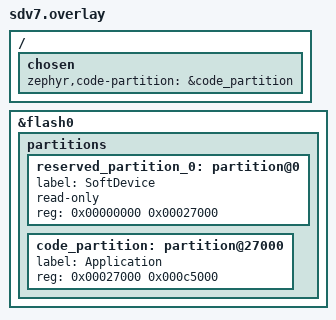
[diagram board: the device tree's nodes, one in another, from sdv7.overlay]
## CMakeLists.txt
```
# SPDX-License-Identifier: Apache-2.0
#
# TouchBridge Digitizer: nRF52840 USB multitouch bridge (CDC ACM in, HID touch screen out)

cmake_minimum_required(VERSION 3.20.0)

find_package(Zephyr REQUIRED HINTS $ENV{ZEPHYR_BASE})
project(touchbridge_digitizer)

target_sources(app PRIVATE src/main.c src/tb_proto.c src/tb_report.c)
```

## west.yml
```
# west manifest for the TouchBridge Digitizer firmware.
# Pins Zephyr (same version as the Auracaster dongle) and fetches only what an
# nRF52840 USB device needs.
manifest:
  self:
    path: nrf-digitizer
  remotes:
    - name: zephyrproject-rtos
      url-base: https://github.com/zephyrproject-rtos
  projects:
    - name: zephyr
      remote: zephyrproject-rtos
      revision: v4.4.2
      import:
        name-allowlist:
          - cmsis_6
          - hal_nordic
```

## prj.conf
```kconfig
# TouchBridge Digitizer - USB composite device (CDC ACM + HID touch screen)

# --- System -------------------------------------------------------------------
CONFIG_GPIO=y
CONFIG_HWINFO=y
CONFIG_RING_BUFFER=y
CONFIG_MAIN_STACK_SIZE=2048
CONFIG_SYSTEM_WORKQUEUE_STACK_SIZE=1024
# no console / logging: the CDC ACM port carries the TouchBridge protocol
CONFIG_CONSOLE=n
CONFIG_STDOUT_CONSOLE=n
CONFIG_UART_CONSOLE=n
CONFIG_LOG=n
CONFIG_SERIAL=y
CONFIG_UART_INTERRUPT_DRIVEN=y
# DTR (host opened the port) and baud rate (1200 baud touch -> UF2 bootloader)
CONFIG_UART_LINE_CTRL=y

# --- USB device stack (device_next) ------------------------------------------
# The board's own CDC ACM boot initialisation is replaced by src/main.c, which
# registers CDC ACM and HID in one configuration (VID/PID 2fe3:0010).
CONFIG_USB_DEVICE_STACK_NEXT=y
CONFIG_CDC_ACM_SERIAL_INITIALIZE_AT_BOOT=n
CONFIG_USBD_CDC_ACM_CLASS=y
CONFIG_USBD_HID_SUPPORT=y
# 1 report in flight + 1 spare
CONFIG_USBD_HID_IN_BUF_COUNT=2
```

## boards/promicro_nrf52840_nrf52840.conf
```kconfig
# "nosd" variant: board promicro_nrf52840/nrf52840 (without /uf2).
# Linked at 0x1000 right behind the Nordic MBR, for clones whose UF2
# bootloader reports "SoftDevice: not found" in INFO_UF2.TXT.
CONFIG_BUILD_OUTPUT_UF2=y
```

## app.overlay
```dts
/*
 * HID touch screen interface of the TouchBridge Digitizer. The CDC ACM
 * interface is the board's board_cdc_acm_uart node (boards/common/usb/cdc_acm_serial.dtsi).
 *
 * SPDX-License-Identifier: Apache-2.0
 */

/ {
	touch_hid: touch_hid {
		compatible = "zephyr,hid-device";
		label = "TouchBridge Digitizer";
		protocol-code = "none";
		/* 1 ms interrupt IN endpoint, 64-byte report 1 (incl. report ID) */
		in-polling-period-us = <1000>;
		in-report-size = <64>;
	};
};
```

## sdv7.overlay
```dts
/*
 * Optional layout for UF2 bootloaders shipped with SoftDevice S140 v7.x
 * (INFO_UF2.TXT: "SoftDevice: S140 version 7.x.x"): application at 0x27000.
 * Applied on top of promicro_nrf52840/nrf52840/uf2 (default: S140 v6, 0x26000).
 *
 * SPDX-License-Identifier: Apache-2.0
 */

/delete-node/ &reserved_partition_0;
/delete-node/ &code_partition;

/ {
	chosen {
		zephyr,code-partition = &code_partition;
	};
};

&flash0 {
	partitions {
		reserved_partition_0: partition@0 {
			label = "SoftDevice";
			read-only;
			reg = <0x00000000 0x00027000>;
		};

		code_partition: partition@27000 {
			label = "Application";
			reg = <0x00027000 0x000c5000>;
		};
	};
};
```

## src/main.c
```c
/*
 * TouchBridge Digitizer - nRF52840 USB multitouch bridge (Pro Micro nRF52840 / nice!nano v2).
 *
 * USB composite device 2fe3:0010 "TouchBridge Digitizer" (Zephyr device_next stack):
 *   - CDC ACM: TouchBridge on the Mac sends contact frames (PROTOCOL.md)
 *   - HID touch screen (Digitizer 0x0D / Touch Screen 0x04, 10 contacts):
 *     every frame is re-emitted as HID input report 1, so macOS sees a real
 *     USB digitizer instead of synthetic events.
 *
 * Safety: all contacts are lifted when no frame arrives for 200 ms while a
 * finger is down, when the host closes the port (DTR 0) and on TB_MSG_RELEASE_ALL.
 * "1200 baud touch" or TB_MSG_BOOTLOADER reboots into the UF2 bootloader.
 *
 * SPDX-License-Identifier: Apache-2.0
 */

#include <string.h>

#include <zephyr/kernel.h>
#include <zephyr/device.h>
#include <zephyr/drivers/gpio.h>
#include <zephyr/drivers/uart.h>
#include <zephyr/linker/linker-defs.h>
#include <zephyr/sys/ring_buffer.h>
#include <zephyr/sys/atomic.h>
#include <zephyr/usb/usbd.h>
#include <zephyr/usb/class/usbd_hid.h>

#include <soc.h>
#include <app_version.h>

#include "tb_proto.h"
#include "tb_report.h"

#define TB_VID 0x2FE3
#define TB_PID 0x0010

#define RELEASE_TIMEOUT_MS 200
#define TOUCH_BAUD         1200U
#define UF2_RESET_MAGIC    0x57 /* DFU_MAGIC_UF2_RESET (Adafruit nRF52 bootloader) */

/* hello reply flags */
#define HELLO_FLAG_BOOTLOADER_CMD BIT(0)
#define HELLO_FLAG_TOUCH_1200     BIT(1)

static const uint8_t hid_report_desc[] = {
#include "hid_report_desc.inc"
};

static const struct device *const cdc_dev = DEVICE_DT_GET(DT_NODELABEL(board_cdc_acm_uart));
static const struct device *const hid_dev = DEVICE_DT_GET(DT_NODELABEL(touch_hid));

/* ------------------------------------------------------------------ USB device */

USBD_DEVICE_DEFINE(tb_usbd, DEVICE_DT_GET(DT_NODELABEL(zephyr_udc0)), TB_VID, TB_PID);
USBD_DESC_LANG_DEFINE(tb_lang);
USBD_DESC_MANUFACTURER_DEFINE(tb_mfr, "TouchBridge");
USBD_DESC_PRODUCT_DEFINE(tb_product, "TouchBridge Digitizer");
USBD_DESC_SERIAL_NUMBER_DEFINE(tb_sn);
USBD_DESC_CONFIG_DEFINE(tb_fs_cfg_desc, "FS Configuration");
/* bus powered, 100 mA */
USBD_CONFIGURATION_DEFINE(tb_fs_config, 0, 50, &tb_fs_cfg_desc);

static int usb_setup(void)
{
	int err;

	err = usbd_add_descriptor(&tb_usbd, &tb_lang);
	err = err ? err : usbd_add_descriptor(&tb_usbd, &tb_mfr);
	err = err ? err : usbd_add_descriptor(&tb_usbd, &tb_product);
	err = err ? err : usbd_add_descriptor(&tb_usbd, &tb_sn);
	err = err ? err : usbd_add_configuration(&tb_usbd, USBD_SPEED_FS, &tb_fs_config);
	err = err ? err : usbd_register_all_classes(&tb_usbd, USBD_SPEED_FS, 1, NULL);
	if (err) {
		return err;
	}
	/* CDC ACM has an Interface Association Descriptor */
	usbd_device_set_code_triple(&tb_usbd, USBD_SPEED_FS, USB_BCC_MISCELLANEOUS, 0x02, 0x01);
	usbd_self_powered(&tb_usbd, false);
	err = usbd_init(&tb_usbd);
	return err ? err : usbd_enable(&tb_usbd);
}

/* ------------------------------------------------------------------ status LED */

enum led_mode { LED_NO_USB, LED_WAITING, LED_CONNECTED, LED_TOUCHING };
static atomic_t led_mode = ATOMIC_INIT(LED_NO_USB);

#if DT_NODE_EXISTS(DT_ALIAS(led0))
static const struct gpio_dt_spec led = GPIO_DT_SPEC_GET(DT_ALIAS(led0), gpios);

/*   no USB host      : short blip every 2 s
 *   USB, port closed : slow blink (1 Hz)
 *   TouchBridge open : steady on
 *   finger(s) down   : fast blink (5 Hz)
 */
static void led_thread(void *a, void *b, void *c)
{
	ARG_UNUSED(a); ARG_UNUSED(b); ARG_UNUSED(c);
	uint32_t tick = 0;

	if (!gpio_is_ready_dt(&led) || gpio_pin_configure_dt(&led, GPIO_OUTPUT_INACTIVE)) {
		return;
	}
	while (true) {
		bool on;

		switch (atomic_get(&led_mode)) {
		case LED_TOUCHING:  on = (tick & 1U) == 0U; break;
		case LED_CONNECTED: on = true; break;
		case LED_WAITING:   on = (tick % 10U) < 5U; break;
		default:            on = (tick % 20U) == 0U; break;
		}
		gpio_pin_set_dt(&led, on);
		tick++;
		k_msleep(100);
	}
}
K_THREAD_DEFINE(led_tid, 512, led_thread, NULL, NULL, NULL, K_LOWEST_APPLICATION_THREAD_PRIO, 0, 0);
#endif

/* ------------------------------------------------------------------ CDC ACM */

RING_BUF_DECLARE(rx_ring, 1024);
RING_BUF_DECLARE(tx_ring, 256);
static K_SEM_DEFINE(wake_sem, 0, 1);

static void cdc_irq(const struct device *dev, void *user_data)
{
	ARG_UNUSED(user_data);

	while (uart_irq_update(dev) && uart_irq_is_pending(dev)) {
		if (uart_irq_rx_ready(dev)) {
			uint8_t buf[64];
			int n = uart_fifo_read(dev, buf, sizeof(buf));

			if (n > 0) {
				(void)ring_buf_put(&rx_ring, buf, n); /* overflow: bytes dropped, CRC catches it */
				k_sem_give(&wake_sem);
			}
		}
		if (uart_irq_tx_ready(dev)) {
			uint8_t buf[64];
			uint32_t n = ring_buf_peek(&tx_ring, buf, sizeof(buf));

			if (n == 0) {
				uart_irq_tx_disable(dev);
			} else {
				int sent = uart_fifo_fill(dev, buf, n);

				if (sent > 0) {
					ring_buf_get(&tx_ring, NULL, sent);
				}
			}
		}
	}
}

static void send_msg(const uint8_t *payload, uint8_t len)
{
	uint8_t frame[TB_MAX_PAYLOAD + 3];
	size_t n = tb_encode_frame(payload, len, frame, sizeof(frame));

	if (n == 0) {
		return;
	}
	unsigned int key = irq_lock();

	if (ring_buf_space_get(&tx_ring) >= n) {
		ring_buf_put(&tx_ring, frame, n);
	}
	irq_unlock(key);
	uart_irq_tx_enable(cdc_dev);
}

/* ------------------------------------------------------------------ firmware identity */

static uint8_t fw_variant(void)
{
	switch ((uint32_t)(uintptr_t)_vector_start) {
	case 0x26000: return 1; /* s140v6 */
	case 0x27000: return 2; /* s140v7 */
	case 0x1000:  return 3; /* nosd   */
	default:      return 0;
	}
}

static void send_hello_reply(void)
{
	uint32_t load = (uint32_t)(uintptr_t)_vector_start;
	uint8_t p[] = {
		TB_MSG_HELLO_REPLY, TB_PROTO_VERSION,
		APP_VERSION_MAJOR, APP_VERSION_MINOR, APP_PATCHLEVEL,
		TB_MAX_CONTACTS, fw_variant(), HELLO_FLAG_BOOTLOADER_CMD | HELLO_FLAG_TOUCH_1200,
		(uint8_t)load, (uint8_t)(load >> 8), (uint8_t)(load >> 16), (uint8_t)(load >> 24),
		'T', 'B', 'D', 'G',
	};

	send_msg(p, sizeof(p));
}

static void send_error(uint8_t code)
{
	uint8_t p[] = { TB_MSG_ERROR, code };

	send_msg(p, sizeof(p));
}

static FUNC_NORETURN void enter_uf2_bootloader(void)
{
	(void)irq_lock();
	/* read and cleared by the Adafruit nRF52 bootloader after reset */
	NRF_POWER->GPREGRET = UF2_RESET_MAGIC;
	NVIC_SystemReset();
	CODE_UNREACHABLE;
}

/* ------------------------------------------------------------------ HID */

static atomic_t hid_ready;
static atomic_t hid_busy;
static struct tb_report_state rstate;
/* latest report waiting for the IN endpoint (coalesced while one is in flight) */
static uint8_t pending_report[TB_REPORT_SIZE];
static bool have_pending;
UDC_STATIC_BUF_DEFINE(tx_report, TB_REPORT_SIZE);

static void hid_iface_ready(const struct device *dev, const bool ready)
{
	ARG_UNUSED(dev);
	atomic_set(&hid_ready, ready);
	if (!ready) {
		atomic_set(&hid_busy, 0);
	}
	k_sem_give(&wake_sem);
}

static int hid_get_report(const struct device *dev, const uint8_t type, const uint8_t id,
			  const uint16_t len, uint8_t *const buf)
{
	ARG_UNUSED(dev);
	if (type == HID_REPORT_TYPE_FEATURE && id == TB_REPORT_ID_MAX_COUNT && len >= 2) {
		buf[0] = TB_REPORT_ID_MAX_COUNT;
		buf[1] = TB_MAX_CONTACTS;
		return 2;
	}
	if (type == HID_REPORT_TYPE_INPUT && id == TB_REPORT_ID_INPUT && len >= TB_REPORT_SIZE) {
		/* current state: nothing down after a GET_REPORT is acceptable */
		memset(buf, 0, TB_REPORT_SIZE);
		buf[0] = TB_REPORT_ID_INPUT;
		return TB_REPORT_SIZE;
	}
	return -ENOTSUP;
}

static int hid_set_report(const struct device *dev, const uint8_t type, const uint8_t id,
			  const uint16_t len, const uint8_t *const buf)
{
	ARG_UNUSED(dev); ARG_UNUSED(type); ARG_UNUSED(id); ARG_UNUSED(len); ARG_UNUSED(buf);
	return 0; /* nothing configurable; accept so hosts do not stall */
}

static void hid_report_done(const struct device *dev, const uint8_t *const report)
{
	ARG_UNUSED(dev); ARG_UNUSED(report);
	atomic_set(&hid_busy, 0);
	k_sem_give(&wake_sem);
}

static const struct hid_device_ops hid_ops = {
	.iface_ready = hid_iface_ready,
	.get_report = hid_get_report,
	.set_report = hid_set_report,
	.input_report_done = hid_report_done,
};

static void hid_flush(void)
{
	if (!have_pending || !atomic_get(&hid_ready) || atomic_get(&hid_busy)) {
		return;
	}
	memcpy(tx_report, pending_report, TB_REPORT_SIZE);
	atomic_set(&hid_busy, 1);
	if (hid_device_submit_report(hid_dev, TB_REPORT_SIZE, tx_report) != 0) {
		atomic_set(&hid_busy, 0);
		return; /* keep it pending, retried on the next wake-up */
	}
	have_pending = false;
}

static uint16_t scan_time(void)
{
	/* 100 us units, wraps at 65535 */
	return (uint16_t)(k_ticks_to_us_floor64(k_uptime_ticks()) / 100U);
}

static void queue_frame(const struct tb_touch_frame *f)
{
	uint8_t old[TB_REPORT_SIZE];
	bool had_pending = have_pending;

	if (had_pending) {
		memcpy(old, pending_report, sizeof(old));
	}
	tb_report_build(&rstate, f, scan_time(), pending_report);
	if (had_pending) {
		/* the unsent report is replaced: keep its lifts (tip = 0 entries),
		 * otherwise the OS would never see those contacts go up */
		tb_report_merge_lifts(pending_report, old);
	}
	have_pending = true;
	hid_flush();
}

static void release_all(void)
{
	if (!tb_report_any_down(&rstate)) {
		return;
	}
	struct tb_touch_frame none = { .count = 0 };

	queue_frame(&none);
}

/* ------------------------------------------------------------------ main loop */

static void handle_payload(const uint8_t *p, int len, int64_t *last_frame)
{
	switch (p[0]) {
	case TB_MSG_TOUCH: {
		struct tb_touch_frame f;
		int err = tb_decode_touch(p, (size_t)len, &f);

		if (err) {
			send_error((uint8_t)err);
			return;
		}
		*last_frame = k_uptime_get();
		queue_frame(&f);
		break;
	}
	case TB_MSG_HELLO:
		send_hello_reply();
		break;
	case TB_MSG_RELEASE_ALL:
		release_all();
		break;
	case TB_MSG_BOOTLOADER:
		k_msleep(50);
		enter_uf2_bootloader();
	default:
		send_error(TB_ERR_TYPE);
		break;
	}
}

int main(void)
{
	static struct tb_parser parser;
	int64_t last_frame = 0;
	uint32_t last_dtr = 0;

	tb_parser_init(&parser);
	tb_report_init(&rstate);

	if (!device_is_ready(cdc_dev) || !device_is_ready(hid_dev)) {
		return 0;
	}
	if (hid_device_register(hid_dev, hid_report_desc, sizeof(hid_report_desc), &hid_ops)) {
		return 0;
	}
	if (usb_setup()) {
		return 0;
	}
	uart_irq_callback_set(cdc_dev, cdc_irq);
	uart_irq_rx_enable(cdc_dev);

	while (true) {
		(void)k_sem_take(&wake_sem, K_MSEC(20));

		uint8_t buf[64];
		uint32_t n;

		while ((n = ring_buf_get(&rx_ring, buf, sizeof(buf))) > 0) {
			for (uint32_t i = 0; i < n; i++) {
				int len = tb_parser_feed(&parser, buf[i]);

				if (len > 0) {
					handle_payload(parser.buf, len, &last_frame);
				}
			}
		}

		/* host port state: DTR drop releases everything; 1200 baud touch -> bootloader */
		uint32_t dtr = 0, baud = 0;

		(void)uart_line_ctrl_get(cdc_dev, UART_LINE_CTRL_DTR, &dtr);
		if (uart_line_ctrl_get(cdc_dev, UART_LINE_CTRL_BAUD_RATE, &baud) == 0 &&
		    baud == TOUCH_BAUD && dtr == 0U) {
			release_all();
			k_msleep(50);
			enter_uf2_bootloader();
		}
		if (last_dtr && !dtr) {
			release_all();
			tb_parser_init(&parser);
		}
		last_dtr = dtr;

		if (tb_report_any_down(&rstate) && k_uptime_get() - last_frame > RELEASE_TIMEOUT_MS) {
			release_all();
		}
		hid_flush();

		if (!atomic_get(&hid_ready)) {
			atomic_set(&led_mode, LED_NO_USB);
		} else if (!dtr) {
			atomic_set(&led_mode, LED_WAITING);
		} else {
			atomic_set(&led_mode, tb_report_any_down(&rstate) ? LED_TOUCHING : LED_CONNECTED);
		}
	}
	return 0;
}
```

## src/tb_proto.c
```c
/*
 * TouchBridge Digitizer serial protocol, see tb_proto.h and ../PROTOCOL.md.
 *
 * SPDX-License-Identifier: Apache-2.0
 */
#include "tb_proto.h"

#include <string.h>

enum { ST_SYNC, ST_LEN, ST_PAYLOAD, ST_CRC };

uint8_t tb_crc8(const uint8_t *data, size_t len)
{
	uint8_t crc = 0x00;

	for (size_t i = 0; i < len; i++) {
		crc ^= data[i];
		for (int b = 0; b < 8; b++) {
			crc = (crc & 0x80) ? (uint8_t)((crc << 1) ^ 0x07) : (uint8_t)(crc << 1);
		}
	}
	return crc;
}

void tb_parser_init(struct tb_parser *p)
{
	memset(p, 0, sizeof(*p));
	p->state = ST_SYNC;
}

int tb_parser_feed(struct tb_parser *p, uint8_t byte)
{
	switch (p->state) {
	case ST_SYNC:
		if (byte == TB_SYNC) {
			p->state = ST_LEN;
		}
		return 0;
	case ST_LEN:
		if (byte == 0 || byte > TB_MAX_PAYLOAD) {
			p->length_errors++;
			/* a sync byte here may start the real frame */
			p->state = (byte == TB_SYNC) ? ST_LEN : ST_SYNC;
			return 0;
		}
		p->len = byte;
		p->pos = 0;
		p->state = ST_PAYLOAD;
		return 0;
	case ST_PAYLOAD:
		p->buf[p->pos++] = byte;
		if (p->pos >= p->len) {
			p->state = ST_CRC;
		}
		return 0;
	case ST_CRC: {
		/* CRC covers LEN + payload */
		uint8_t tmp[TB_MAX_PAYLOAD + 1];
		uint8_t crc;

		tmp[0] = p->len;
		memcpy(&tmp[1], p->buf, p->len);
		crc = tb_crc8(tmp, (size_t)p->len + 1U);
		p->state = ST_SYNC;
		if (crc != byte) {
			p->crc_errors++;
			return 0;
		}
		return p->len;
	}
	default:
		p->state = ST_SYNC;
		return 0;
	}
}

int tb_decode_touch(const uint8_t *payload, size_t len, struct tb_touch_frame *out)
{
	/* type, version, count, count x 6 bytes */
	if (len < 3U || payload[0] != TB_MSG_TOUCH) {
		return TB_ERR_LENGTH;
	}
	if (payload[1] != TB_PROTO_VERSION) {
		return TB_ERR_VERSION;
	}
	uint8_t count = payload[2];

	if (count > TB_MAX_CONTACTS || len != 3U + 6U * count) {
		return TB_ERR_LENGTH;
	}
	out->count = count;
	for (uint8_t i = 0; i < count; i++) {
		const uint8_t *c = &payload[3 + 6 * i];
		uint16_t x = (uint16_t)(c[2] | (c[3] << 8));
		uint16_t y = (uint16_t)(c[4] | (c[5] << 8));

		out->c[i].id = c[0] & 0x7F;
		out->c[i].flags = c[1];
		out->c[i].x = x > TB_COORD_MAX ? TB_COORD_MAX : x;
		out->c[i].y = y > TB_COORD_MAX ? TB_COORD_MAX : y;
	}
	return 0;
}

size_t tb_encode_frame(const uint8_t *payload, uint8_t len, uint8_t *out, size_t out_size)
{
	if (len == 0 || len > TB_MAX_PAYLOAD || out_size < (size_t)len + 3U) {
		return 0;
	}
	out[0] = TB_SYNC;
	out[1] = len;
	memcpy(&out[2], payload, len);
	out[2 + len] = tb_crc8(&out[1], (size_t)len + 1U);
	return (size_t)len + 3U;
}
```

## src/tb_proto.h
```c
/*
 * TouchBridge Digitizer serial protocol (host <-> dongle over USB CDC ACM).
 * Pure C, no Zephyr dependencies: also compiled natively by the CI host test
 * (tests/proto_test.c). Wire format: see ../PROTOCOL.md.
 *
 * SPDX-License-Identifier: Apache-2.0
 */
#ifndef TB_PROTO_H_
#define TB_PROTO_H_

#include <stdbool.h>
#include <stddef.h>
#include <stdint.h>

#define TB_SYNC             0xA5
#define TB_PROTO_VERSION    1
#define TB_MAX_PAYLOAD      64
#define TB_MAX_CONTACTS     10
#define TB_COORD_MAX        32767

/* message types (first payload byte) */
#define TB_MSG_TOUCH        0x01 /* host -> dongle: contact frame               */
#define TB_MSG_HELLO        0x02 /* host -> dongle: who are you?                */
#define TB_MSG_RELEASE_ALL  0x03 /* host -> dongle: lift every contact now      */
#define TB_MSG_BOOTLOADER   0x04 /* host -> dongle: reboot into UF2 bootloader  */
#define TB_MSG_HELLO_REPLY  0x82 /* dongle -> host: identity + version          */
#define TB_MSG_ERROR        0x8F /* dongle -> host: frame rejected (code)       */

/* contact flags */
#define TB_FLAG_TIP         0x01
#define TB_FLAG_CONFIDENCE  0x02

/* TB_MSG_ERROR codes */
#define TB_ERR_CRC          1
#define TB_ERR_LENGTH       2
#define TB_ERR_VERSION      3
#define TB_ERR_TYPE         4

struct tb_contact {
	uint8_t id;     /* 0..127 */
	uint8_t flags;  /* TB_FLAG_* */
	uint16_t x;     /* 0..32767 */
	uint16_t y;     /* 0..32767 */
};

struct tb_touch_frame {
	uint8_t count;
	struct tb_contact c[TB_MAX_CONTACTS];
};

/* CRC-8, polynomial 0x07, init 0x00, no reflection (CRC-8/SMBUS) */
uint8_t tb_crc8(const uint8_t *data, size_t len);

/* Byte-wise stream parser */
struct tb_parser {
	uint8_t state;
	uint8_t len;
	uint8_t pos;
	uint8_t buf[TB_MAX_PAYLOAD];
	uint32_t crc_errors;
	uint32_t length_errors;
};

void tb_parser_init(struct tb_parser *p);

/*
 * Feed one byte. Returns the payload length (>0) when a complete frame with a
 * valid CRC is in p->buf, 0 otherwise. A bad length or CRC drops the frame;
 * the parser then waits for the next sync byte.
 */
int tb_parser_feed(struct tb_parser *p, uint8_t byte);

/*
 * Decode a TB_MSG_TOUCH payload. Returns 0 or a TB_ERR_* code.
 * Coordinates are clamped to TB_COORD_MAX, ids masked to 0..127.
 */
int tb_decode_touch(const uint8_t *payload, size_t len, struct tb_touch_frame *out);

/* Wrap a payload into a frame (sync, len, payload, crc). Returns frame size. */
size_t tb_encode_frame(const uint8_t *payload, uint8_t len, uint8_t *out, size_t out_size);

#endif /* TB_PROTO_H_ */
```

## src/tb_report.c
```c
/*
 * SPDX-License-Identifier: Apache-2.0
 */
#include "tb_report.h"

#include <string.h>

static bool bit_get(const uint8_t *m, uint8_t id) { return (m[id >> 3] >> (id & 7)) & 1U; }
static void bit_set(uint8_t *m, uint8_t id) { m[id >> 3] |= (uint8_t)(1U << (id & 7)); }

void tb_report_init(struct tb_report_state *s)
{
	memset(s, 0, sizeof(*s));
}

bool tb_report_any_down(const struct tb_report_state *s)
{
	for (size_t i = 0; i < sizeof(s->down); i++) {
		if (s->down[i]) {
			return true;
		}
	}
	return false;
}

static void put_contact(uint8_t *out, uint8_t slot, uint8_t id, bool tip, uint16_t x, uint16_t y)
{
	uint8_t *c = &out[1 + slot * TB_CONTACT_BYTES];

	c[0] = (tip ? 0x01 : 0x00) | 0x02; /* tip switch, confidence (always 1: no palm rejection) */
	c[1] = id & 0x7F;
	c[2] = (uint8_t)(x & 0xFF);
	c[3] = (uint8_t)(x >> 8);
	c[4] = (uint8_t)(y & 0xFF);
	c[5] = (uint8_t)(y >> 8);
}

uint8_t tb_report_build(struct tb_report_state *s, const struct tb_touch_frame *f,
			uint16_t scan_time, uint8_t out[TB_REPORT_SIZE])
{
	uint8_t next[16] = {0};
	uint8_t seen[16] = {0};
	uint8_t n = 0;

	memset(out, 0, TB_REPORT_SIZE);
	out[0] = TB_REPORT_ID_INPUT;

	for (uint8_t i = 0; i < f->count && n < TB_MAX_CONTACTS; i++) {
		const struct tb_contact *c = &f->c[i];
		uint8_t id = c->id & 0x7F;
		bool tip = (c->flags & TB_FLAG_TIP) != 0;

		if (bit_get(seen, id)) {
			continue; /* duplicate id in one frame */
		}
		bit_set(seen, id);
		if (!tip && !bit_get(s->down, id)) {
			continue; /* lift of a contact the OS never saw */
		}
		put_contact(out, n++, id, tip, c->x, c->y);
		s->last_x[id] = c->x;
		s->last_y[id] = c->y;
		if (tip) {
			bit_set(next, id);
		}
	}
	/* contacts that disappeared from the frame: lift them once */
	for (uint16_t id = 0; id < 128; id++) {
		if (!bit_get(s->down, (uint8_t)id) || bit_get(seen, (uint8_t)id)) {
			continue;
		}
		if (n < TB_MAX_CONTACTS) {
			put_contact(out, n++, (uint8_t)id, false, s->last_x[id], s->last_y[id]);
		} else {
			bit_set(next, (uint8_t)id); /* no room: still down, lifted next time */
		}
	}
	memcpy(s->down, next, sizeof(next));

	uint8_t *tail = &out[1 + TB_MAX_CONTACTS * TB_CONTACT_BYTES];

	tail[0] = (uint8_t)(scan_time & 0xFF);
	tail[1] = (uint8_t)(scan_time >> 8);
	tail[2] = n;
	return n;
}

void tb_report_merge_lifts(uint8_t report[TB_REPORT_SIZE], const uint8_t older[TB_REPORT_SIZE])
{
	uint8_t *count = &report[1 + TB_MAX_CONTACTS * TB_CONTACT_BYTES + 2];
	uint8_t old_count = older[1 + TB_MAX_CONTACTS * TB_CONTACT_BYTES + 2];

	for (uint8_t i = 0; i < old_count && i < TB_MAX_CONTACTS; i++) {
		const uint8_t *oc = &older[1 + i * TB_CONTACT_BYTES];
		bool present = false;

		if (oc[0] & 0x01) {
			continue; /* was down: still down or lifted by the newer report */
		}
		for (uint8_t k = 0; k < *count; k++) {
			if (report[1 + k * TB_CONTACT_BYTES + 1] == oc[1]) {
				present = true;
				break;
			}
		}
		if (!present && *count < TB_MAX_CONTACTS) {
			memcpy(&report[1 + *count * TB_CONTACT_BYTES], oc, TB_CONTACT_BYTES);
			(*count)++;
		}
	}
}
```

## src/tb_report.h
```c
/*
 * Builds HID input report 1 of the TouchBridge Digitizer (hid_report_desc.inc)
 * from protocol frames. Pure C, also compiled by the CI host test.
 *
 * SPDX-License-Identifier: Apache-2.0
 */
#ifndef TB_REPORT_H_
#define TB_REPORT_H_

#include <stdbool.h>
#include <stdint.h>

#include "tb_proto.h"

#define TB_REPORT_ID_INPUT      1
#define TB_REPORT_ID_MAX_COUNT  2
#define TB_REPORT_SIZE          64 /* incl. report ID */
#define TB_CONTACT_BYTES        6

struct tb_report_state {
	uint8_t down[16]; /* bitmap: contact ids reported with tip = 1 last time */
	uint16_t last_x[128]; /* last position per id (used for the lift report) */
	uint16_t last_y[128];
};

void tb_report_init(struct tb_report_state *s);
bool tb_report_any_down(const struct tb_report_state *s);

/*
 * Fill out[TB_REPORT_SIZE] from a frame. Contacts that were down before and
 * are missing from the frame are added once with tip = 0, so the OS always
 * sees a lift. Returns the number of contacts in the report.
 * A frame with count 0 lifts every contact that is down.
 */
uint8_t tb_report_build(struct tb_report_state *s, const struct tb_touch_frame *f,
			uint16_t scan_time, uint8_t out[TB_REPORT_SIZE]);

/*
 * Copy the lift entries (tip = 0) of an unsent report `older` into `report`
 * when their id is not in `report` yet and a slot is free.
 */
void tb_report_merge_lifts(uint8_t report[TB_REPORT_SIZE], const uint8_t older[TB_REPORT_SIZE]);

#endif /* TB_REPORT_H_ */
```
